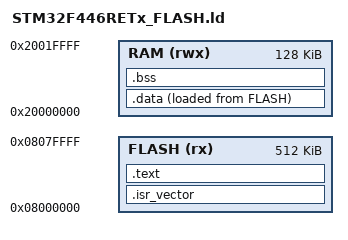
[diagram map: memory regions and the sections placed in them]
/* Linker script for STM32F446RE */

/* Memory layout for STM32F446RE */
MEMORY
{
    FLASH (rx)  : ORIGIN = 0x08000000, LENGTH = 512K
    RAM (rwx)   : ORIGIN = 0x20000000, LENGTH = 128K
}

/* Entry point */
ENTRY(Reset_Handler)

/* Stack size */
_estack = ORIGIN(RAM) + LENGTH(RAM);

SECTIONS
{
    /* Vector table and code */
    .isr_vector :
    {
        . = ALIGN(4);
        KEEP(*(.isr_vector))
        . = ALIGN(4);
    } > FLASH

    .text :
    {
        . = ALIGN(4);
        *(.text)
        *(.text*)
        *(.rodata)
        *(.rodata*)
        . = ALIGN(4);
        _etext = .;
    } > FLASH

    /* Data that needs to be copied to RAM */
    .data :
    {
        . = ALIGN(4);
        _sdata = .;
        *(.data)
        *(.data*)
        . = ALIGN(4);
        _edata = .;
    } > RAM AT> FLASH

    _sidata = LOADADDR(.data);

    /* Uninitialized data */
    .bss :
    {
        . = ALIGN(4);
        _sbss = .;
        *(.bss)
        *(.bss*)
        *(COMMON)
        . = ALIGN(4);
        _ebss = .;
        _end = .;  /* Symbol for heap start */
    } > RAM
}
